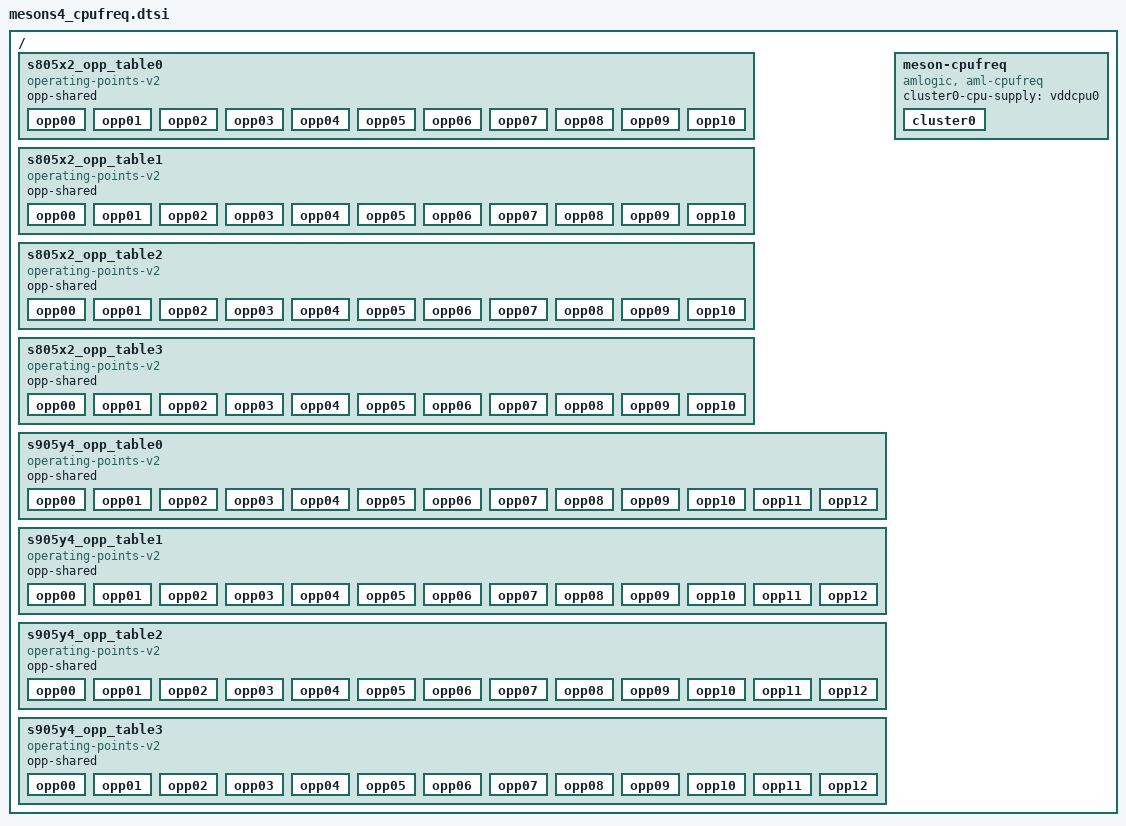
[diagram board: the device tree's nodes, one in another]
// SPDX-License-Identifier: (GPL-2.0+ OR MIT)
/*
 * Copyright (c) 2019 Amlogic, Inc. All rights reserved.
 */

/ {
	s805x2_opp_table0: s805x2_opp_table0 {
		compatible = "operating-points-v2";
		status = "okay";
		opp-shared;

		opp00 {
			opp-hz = /bits/ 64 <100000000>;
			opp-microvolt = <769000>;
		};
		opp01 {
			opp-hz = /bits/ 64 <250000000>;
			opp-microvolt = <769000>;
		};
		opp02 {
			opp-hz = /bits/ 64 <500000000>;
			opp-microvolt = <769000>;
		};
		opp03 {
			opp-hz = /bits/ 64 <666666666>;
			opp-microvolt = <769000>;
		};
		opp04 {
			opp-hz = /bits/ 64 <1000000000>;
			opp-microvolt = <769000>;
		};
		opp05 {
			opp-hz = /bits/ 64 <1200000000>;
			opp-microvolt = <769000>;
		};
		opp06 {
			opp-hz = /bits/ 64 <1404000000>;
			opp-microvolt = <799000>;
		};
		opp07 {
			opp-hz = /bits/ 64 <1500000000>;
			opp-microvolt = <829000>;
		};
		opp08 {
			opp-hz = /bits/ 64 <1608000000>;
			opp-microvolt = <869000>;
		};
		opp09 {
			opp-hz = /bits/ 64 <1704000000>;
			opp-microvolt = <909000>;
		};
		opp10 {
			opp-hz = /bits/ 64 <1800000000>;
			opp-microvolt = <1009000>;
		};
	};

	s805x2_opp_table1: s805x2_opp_table1 {
		compatible = "operating-points-v2";
		status = "okay";
		opp-shared;

		opp00 {
			opp-hz = /bits/ 64 <100000000>;
			opp-microvolt = <769000>;
		};
		opp01 {
			opp-hz = /bits/ 64 <250000000>;
			opp-microvolt = <769000>;
		};
		opp02 {
			opp-hz = /bits/ 64 <500000000>;
			opp-microvolt = <769000>;
		};
		opp03 {
			opp-hz = /bits/ 64 <666666666>;
			opp-microvolt = <769000>;
		};
		opp04 {
			opp-hz = /bits/ 64 <1000000000>;
			opp-microvolt = <769000>;
		};
		opp05 {
			opp-hz = /bits/ 64 <1200000000>;
			opp-microvolt = <769000>;
		};
		opp06 {
			opp-hz = /bits/ 64 <1404000000>;
			opp-microvolt = <799000>;
		};
		opp07 {
			opp-hz = /bits/ 64 <1500000000>;
			opp-microvolt = <829000>;
		};
		opp08 {
			opp-hz = /bits/ 64 <1608000000>;
			opp-microvolt = <869000>;
		};
		opp09 {
			opp-hz = /bits/ 64 <1704000000>;
			opp-microvolt = <909000>;
		};
		opp10 {
			opp-hz = /bits/ 64 <1800000000>;
			opp-microvolt = <1009000>;
		};
	};

	s805x2_opp_table2: s805x2_opp_table2 {
		compatible = "operating-points-v2";
		status = "okay";
		opp-shared;

		opp00 {
			opp-hz = /bits/ 64 <100000000>;
			opp-microvolt = <759000>;
		};
		opp01 {
			opp-hz = /bits/ 64 <250000000>;
			opp-microvolt = <759000>;
		};
		opp02 {
			opp-hz = /bits/ 64 <500000000>;
			opp-microvolt = <759000>;
		};
		opp03 {
			opp-hz = /bits/ 64 <666666666>;
			opp-microvolt = <759000>;
		};
		opp04 {
			opp-hz = /bits/ 64 <1000000000>;
			opp-microvolt = <759000>;
		};
		opp05 {
			opp-hz = /bits/ 64 <1200000000>;
			opp-microvolt = <759000>;
		};
		opp06 {
			opp-hz = /bits/ 64 <1404000000>;
			opp-microvolt = <759000>;
		};
		opp07 {
			opp-hz = /bits/ 64 <1500000000>;
			opp-microvolt = <769000>;
		};
		opp08 {
			opp-hz = /bits/ 64 <1608000000>;
			opp-microvolt = <799000>;
		};
		opp09 {
			opp-hz = /bits/ 64 <1704000000>;
			opp-microvolt = <829000>;
		};
		opp10 {
			opp-hz = /bits/ 64 <1800000000>;
			opp-microvolt = <999000>;
		};
	};

	s805x2_opp_table3: s805x2_opp_table3 {
		compatible = "operating-points-v2";
		status = "okay";
		opp-shared;

		opp00 {
			opp-hz = /bits/ 64 <100000000>;
			opp-microvolt = <759000>;
		};
		opp01 {
			opp-hz = /bits/ 64 <250000000>;
			opp-microvolt = <759000>;
		};
		opp02 {
			opp-hz = /bits/ 64 <500000000>;
			opp-microvolt = <759000>;
		};
		opp03 {
			opp-hz = /bits/ 64 <666666666>;
			opp-microvolt = <759000>;
		};
		opp04 {
			opp-hz = /bits/ 64 <1000000000>;
			opp-microvolt = <759000>;
		};
		opp05 {
			opp-hz = /bits/ 64 <1200000000>;
			opp-microvolt = <759000>;
		};
		opp06 {
			opp-hz = /bits/ 64 <1404000000>;
			opp-microvolt = <759000>;
		};
		opp07 {
			opp-hz = /bits/ 64 <1500000000>;
			opp-microvolt = <759000>;
		};
		opp08 {
			opp-hz = /bits/ 64 <1608000000>;
			opp-microvolt = <769000>;
		};
		opp09 {
			opp-hz = /bits/ 64 <1704000000>;
			opp-microvolt = <809000>;
		};
		opp10 {
			opp-hz = /bits/ 64 <1800000000>;
			opp-microvolt = <939000>;
		};
	};

	s905y4_opp_table0: s905y4_opp_table0 {
		compatible = "operating-points-v2";
		status = "okay";
		opp-shared;

		opp00 {
			opp-hz = /bits/ 64 <100000000>;
			opp-microvolt = <769000>;
		};
		opp01 {
			opp-hz = /bits/ 64 <250000000>;
			opp-microvolt = <769000>;
		};
		opp02 {
			opp-hz = /bits/ 64 <500000000>;
			opp-microvolt = <769000>;
		};
		opp03 {
			opp-hz = /bits/ 64 <666666666>;
			opp-microvolt = <769000>;
		};
		opp04 {
			opp-hz = /bits/ 64 <1000000000>;
			opp-microvolt = <769000>;
		};
		opp05 {
			opp-hz = /bits/ 64 <1200000000>;
			opp-microvolt = <769000>;
		};
		opp06 {
			opp-hz = /bits/ 64 <1404000000>;
			opp-microvolt = <799000>;
		};
		opp07 {
			opp-hz = /bits/ 64 <1500000000>;
			opp-microvolt = <829000>;
		};
		opp08 {
			opp-hz = /bits/ 64 <1608000000>;
			opp-microvolt = <869000>;
		};
		opp09 {
			opp-hz = /bits/ 64 <1704000000>;
			opp-microvolt = <909000>;
		};
		opp10 {
			opp-hz = /bits/ 64 <1800000000>;
			opp-microvolt = <959000>;
		};
		opp11 {
			opp-hz = /bits/ 64 <1908000000>;
			opp-microvolt = <979000>;
		};
		opp12 {
			opp-hz = /bits/ 64 <2004000000>;
			opp-microvolt = <1009000>;
		};
	};

	s905y4_opp_table1: s905y4_opp_table1 {
		compatible = "operating-points-v2";
		status = "okay";
		opp-shared;

		opp00 {
			opp-hz = /bits/ 64 <100000000>;
			opp-microvolt = <769000>;
		};
		opp01 {
			opp-hz = /bits/ 64 <250000000>;
			opp-microvolt = <769000>;
		};
		opp02 {
			opp-hz = /bits/ 64 <500000000>;
			opp-microvolt = <769000>;
		};
		opp03 {
			opp-hz = /bits/ 64 <666666666>;
			opp-microvolt = <769000>;
		};
		opp04 {
			opp-hz = /bits/ 64 <1000000000>;
			opp-microvolt = <769000>;
		};
		opp05 {
			opp-hz = /bits/ 64 <1200000000>;
			opp-microvolt = <769000>;
		};
		opp06 {
			opp-hz = /bits/ 64 <1404000000>;
			opp-microvolt = <799000>;
		};
		opp07 {
			opp-hz = /bits/ 64 <1500000000>;
			opp-microvolt = <829000>;
		};
		opp08 {
			opp-hz = /bits/ 64 <1608000000>;
			opp-microvolt = <869000>;
		};
		opp09 {
			opp-hz = /bits/ 64 <1704000000>;
			opp-microvolt = <909000>;
		};
		opp10 {
			opp-hz = /bits/ 64 <1800000000>;
			opp-microvolt = <959000>;
		};
		opp11 {
			opp-hz = /bits/ 64 <1908000000>;
			opp-microvolt = <979000>;
		};
		opp12 {
			opp-hz = /bits/ 64 <2004000000>;
			opp-microvolt = <1009000>;
		};
	};

	s905y4_opp_table2: s905y4_opp_table2 {
		compatible = "operating-points-v2";
		status = "okay";
		opp-shared;

		opp00 {
			opp-hz = /bits/ 64 <100000000>;
			opp-microvolt = <759000>;
		};
		opp01 {
			opp-hz = /bits/ 64 <250000000>;
			opp-microvolt = <759000>;
		};
		opp02 {
			opp-hz = /bits/ 64 <500000000>;
			opp-microvolt = <759000>;
		};
		opp03 {
			opp-hz = /bits/ 64 <666666666>;
			opp-microvolt = <759000>;
		};
		opp04 {
			opp-hz = /bits/ 64 <1000000000>;
			opp-microvolt = <759000>;
		};
		opp05 {
			opp-hz = /bits/ 64 <1200000000>;
			opp-microvolt = <759000>;
		};
		opp06 {
			opp-hz = /bits/ 64 <1404000000>;
			opp-microvolt = <759000>;
		};
		opp07 {
			opp-hz = /bits/ 64 <1500000000>;
			opp-microvolt = <769000>;
		};
		opp08 {
			opp-hz = /bits/ 64 <1608000000>;
			opp-microvolt = <799000>;
		};
		opp09 {
			opp-hz = /bits/ 64 <1704000000>;
			opp-microvolt = <829000>;
		};
		opp10 {
			opp-hz = /bits/ 64 <1800000000>;
			opp-microvolt = <929000>;
		};
		opp11 {
			opp-hz = /bits/ 64 <1908000000>;
			opp-microvolt = <959000>;
		};
		opp12 {
			opp-hz = /bits/ 64 <2004000000>;
			opp-microvolt = <999000>;
		};
	};

	s905y4_opp_table3: s905y4_opp_table3 {
		compatible = "operating-points-v2";
		status = "okay";
		opp-shared;

		opp00 {
			opp-hz = /bits/ 64 <100000000>;
			opp-microvolt = <759000>;
		};
		opp01 {
			opp-hz = /bits/ 64 <250000000>;
			opp-microvolt = <759000>;
		};
		opp02 {
			opp-hz = /bits/ 64 <500000000>;
			opp-microvolt = <759000>;
		};
		opp03 {
			opp-hz = /bits/ 64 <666666666>;
			opp-microvolt = <759000>;
		};
		opp04 {
			opp-hz = /bits/ 64 <1000000000>;
			opp-microvolt = <759000>;
		};
		opp05 {
			opp-hz = /bits/ 64 <1200000000>;
			opp-microvolt = <759000>;
		};
		opp06 {
			opp-hz = /bits/ 64 <1404000000>;
			opp-microvolt = <759000>;
		};
		opp07 {
			opp-hz = /bits/ 64 <1500000000>;
			opp-microvolt = <759000>;
		};
		opp08 {
			opp-hz = /bits/ 64 <1608000000>;
			opp-microvolt = <769000>;
		};
		opp09 {
			opp-hz = /bits/ 64 <1704000000>;
			opp-microvolt = <809000>;
		};
		opp10 {
			opp-hz = /bits/ 64 <1800000000>;
			opp-microvolt = <889000>;
		};
		opp11 {
			opp-hz = /bits/ 64 <1908000000>;
			opp-microvolt = <909000>;
		};
		opp12 {
			opp-hz = /bits/ 64 <2004000000>;
			opp-microvolt = <939000>;
		};
	};

	meson-cpufreq {
		compatible = "amlogic, aml-cpufreq";
		status = "okay";

		cluster0-cpu-supply = <&vddcpu0>;

		cluster0 {
			clocks = <&scmi_clk CLKID_CPU_CLK>;
			clock-names = "cpuclk";
			voltage-tolerance = <0>;
			transition_delay_us = <10000>;
			//skip_volt_scaling;
			cluster_cores = <0 1 2 3>;
			pdvfs_enabled;
		};
	};
};/* end of / */
